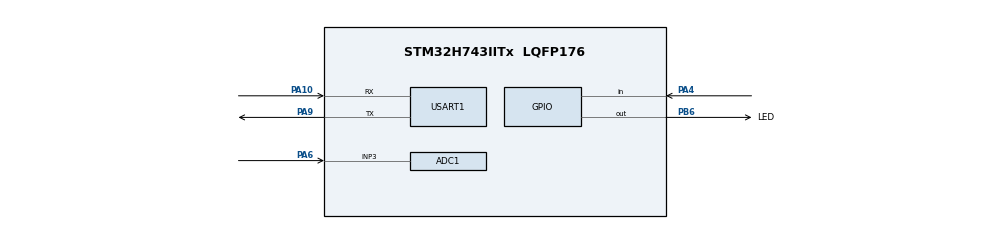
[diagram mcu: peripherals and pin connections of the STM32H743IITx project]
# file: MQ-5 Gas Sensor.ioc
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ADC1.Channel-0\#ChannelRegularConversion=ADC_CHANNEL_3
ADC1.ClockPrescaler=ADC_CLOCK_ASYNC_DIV2
ADC1.NbrOfConversionFlag=1
ADC1.OffsetNumber-0\#ChannelRegularConversion=ADC_OFFSET_NONE
ADC1.OffsetSignedSaturation-0\#ChannelRegularConversion=DISABLE
ADC1.Rank-0\#ChannelRegularConversion=1
ADC1.SamplingTime-0\#ChannelRegularConversion=ADC_SAMPLETIME_1CYCLE_5
ADC1.master=1
Mcu.Family=STM32H7
Mcu.Name=STM32H743IITx
Mcu.Package=LQFP176
NVIC.PriorityGroup=NVIC_PRIORITYGROUP_4
PA10.Mode=Asynchronous
PA10.Signal=USART1_RX
PA13\ (JTMS/SWDIO).Mode=JTAG_5_pins
PA13\ (JTMS/SWDIO).Signal=DEBUG_JTMS-SWDIO
PA14\ (JTCK/SWCLK).Mode=JTAG_5_pins
PA14\ (JTCK/SWCLK).Signal=DEBUG_JTCK-SWCLK
PA15\ (JTDI).Mode=JTAG_5_pins
PA15\ (JTDI).Signal=DEBUG_JTDI
PA4.GPIO_PuPd=GPIO_PULLUP
PA4.Signal=GPIO_Input
PA6.Signal=ADCx_INP3
PA9.Mode=Asynchronous
PA9.Signal=USART1_TX
PB3\ (JTDO/TRACESWO).Mode=JTAG_5_pins
PB3\ (JTDO/TRACESWO).Signal=DEBUG_JTDO-SWO
PB4\ (NJTRST).Mode=JTAG_5_pins
PB4\ (NJTRST).Signal=DEBUG_JTRST
PB6.GPIO_Label=LED
PB6.Signal=GPIO_Output
PH0-OSC_IN\ (PH0).Mode=HSE-External-Oscillator
PH0-OSC_IN\ (PH0).Signal=RCC_OSC_IN
PH1-OSC_OUT\ (PH1).Mode=HSE-External-Oscillator
PH1-OSC_OUT\ (PH1).Signal=RCC_OSC_OUT
ProjectManager.HeapSize=0x200
ProjectManager.StackSize=0x400
ProjectManager.TargetToolchain=MDK-ARM V5
RCC.ADCFreq_Value=72000000
RCC.APB1Freq_Value=120000000
RCC.APB2Freq_Value=120000000
RCC.APB3Freq_Value=120000000
RCC.APB4Freq_Value=120000000
RCC.CortexFreq_Value=480000000
RCC.D1PPRE=RCC_APB3_DIV2
RCC.D2PPRE1=RCC_APB1_DIV2
RCC.D2PPRE2=RCC_APB2_DIV2
RCC.D3PPRE=RCC_APB4_DIV2
RCC.DIVM1=1
RCC.DIVM2=1
RCC.DIVN1=120
RCC.DIVN2=36
RCC.DIVP2=4
RCC.HCLKFreq_Value=240000000
RCC.HPRE=RCC_HCLK_DIV2
RCC.HSE_VALUE=8000000
RCC.PLLSourceVirtual=RCC_PLLSOURCE_HSE
RCC.SYSCLKFreq_VALUE=480000000
RCC.SYSCLKSource=RCC_SYSCLKSOURCE_PLLCLK
RCC.USBFreq_Value=480000000
SH.ADCx_INP3.0=ADC1_INP3,IN3-Single-Ended
USART1.VirtualMode-Asynchronous=VM_ASYNC
board=custom

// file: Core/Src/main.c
/* USER CODE BEGIN Header */
/**
  ******************************************************************************
  * @file           : main.c
  * @brief          : Main program body
  ******************************************************************************
  * @attention
  *
  * <h2><center>&copy; Copyright (c) 2021 STMicroelectronics.
  * All rights reserved.</center></h2>
  *
  * This software component is licensed by ST under BSD 3-Clause license,
  * the "License"; You may not use this file except in compliance with the
  * License. You may obtain a copy of the License at:
  *                        opensource.org/licenses/BSD-3-Clause
  *
  ******************************************************************************
  */
/* USER CODE END Header */
#include "main.h"
#include "adc.h"
#include "usart.h"
#include "gpio.h"

void SystemClock_Config(void);

/* USER CODE BEGIN 0 */
double AD_value;
/* USER CODE END 0 */

int main(void)
{

  /* MCU Configuration--------------------------------------------------------*/

  /* Reset of all peripherals, Initializes the Flash interface and the Systick. */
  HAL_Init();

  /* Configure the system clock */
  SystemClock_Config();

  /* Initialize all configured peripherals */
  MX_GPIO_Init();
  MX_ADC1_Init();
  MX_USART1_UART_Init();

  /* Infinite loop */
  /* USER CODE BEGIN WHILE */
  while (1)
  {
		HAL_ADC_Start(&hadc1);
		AD_value = HAL_ADC_GetValue(&hadc1);
		if(HAL_GPIO_ReadPin(GPIOA , GPIO_PIN_4) == GPIO_PIN_SET)
		{
			HAL_GPIO_WritePin(LED_GPIO_Port, LED_Pin,GPIO_PIN_RESET );
			printf("Gas not leakage!\r\n");
		}
		else
		{
			HAL_GPIO_WritePin(LED_GPIO_Port, LED_Pin,GPIO_PIN_SET );
			printf("Gas leakage!\r\n");
		}
		/* Printf message with AD value to serial port every 1 second */
		AD_value = (AD_value/65536)*3.3;
		printf("The current Gas AD value = %4.2fV \r\n", AD_value);
		HAL_Delay(1000);   /* delay 1000ms */

    /* USER CODE END WHILE */

  }
}

void SystemClock_Config(void)
{
  RCC_OscInitTypeDef RCC_OscInitStruct = {0};
  RCC_ClkInitTypeDef RCC_ClkInitStruct = {0};

  /** Supply configuration update enable
  */
  HAL_PWREx_ConfigSupply(PWR_LDO_SUPPLY);
  /** Configure the main internal regulator output voltage
  */
  __HAL_PWR_VOLTAGESCALING_CONFIG(PWR_REGULATOR_VOLTAGE_SCALE0);

  while(!__HAL_PWR_GET_FLAG(PWR_FLAG_VOSRDY)) {}
  /** Macro to configure the PLL clock source
  */
  __HAL_RCC_PLL_PLLSOURCE_CONFIG(RCC_PLLSOURCE_HSE);
  /** Initializes the RCC Oscillators according to the specified parameters
  * in the RCC_OscInitTypeDef structure.
  */
  RCC_OscInitStruct.OscillatorType = RCC_OSCILLATORTYPE_HSE;
  RCC_OscInitStruct.HSEState = RCC_HSE_ON;
  RCC_OscInitStruct.PLL.PLLState = RCC_PLL_ON;
  RCC_OscInitStruct.PLL.PLLSource = RCC_PLLSOURCE_HSE;
  RCC_OscInitStruct.PLL.PLLM = 1;
  RCC_OscInitStruct.PLL.PLLN = 120;
  RCC_OscInitStruct.PLL.PLLP = 2;
  RCC_OscInitStruct.PLL.PLLQ = 2;
  RCC_OscInitStruct.PLL.PLLR = 2;
  RCC_OscInitStruct.PLL.PLLRGE = RCC_PLL1VCIRANGE_3;
  RCC_OscInitStruct.PLL.PLLVCOSEL = RCC_PLL1VCOWIDE;
  RCC_OscInitStruct.PLL.PLLFRACN = 0;
  if (HAL_RCC_OscConfig(&RCC_OscInitStruct) != HAL_OK)
  {
    Error_Handler();
  }
  /** Initializes the CPU, AHB and APB buses clocks
  */
  RCC_ClkInitStruct.ClockType = RCC_CLOCKTYPE_HCLK|RCC_CLOCKTYPE_SYSCLK
                              |RCC_CLOCKTYPE_PCLK1|RCC_CLOCKTYPE_PCLK2
                              |RCC_CLOCKTYPE_D3PCLK1|RCC_CLOCKTYPE_D1PCLK1;
  RCC_ClkInitStruct.SYSCLKSource = RCC_SYSCLKSOURCE_PLLCLK;
  RCC_ClkInitStruct.SYSCLKDivider = RCC_SYSCLK_DIV1;
  RCC_ClkInitStruct.AHBCLKDivider = RCC_HCLK_DIV2;
  RCC_ClkInitStruct.APB3CLKDivider = RCC_APB3_DIV2;
  RCC_ClkInitStruct.APB1CLKDivider = RCC_APB1_DIV2;
  RCC_ClkInitStruct.APB2CLKDivider = RCC_APB2_DIV2;
  RCC_ClkInitStruct.APB4CLKDivider = RCC_APB4_DIV2;

  if (HAL_RCC_ClockConfig(&RCC_ClkInitStruct, FLASH_LATENCY_4) != HAL_OK)
  {
    Error_Handler();
  }
}

void Error_Handler(void)
{
  __disable_irq();
  while (1)
  {
  }
}

/************************ (C) COPYRIGHT STMicroelectronics *****END OF FILE****/
